VERSION ""

NS_ :

BS_:

BU_:

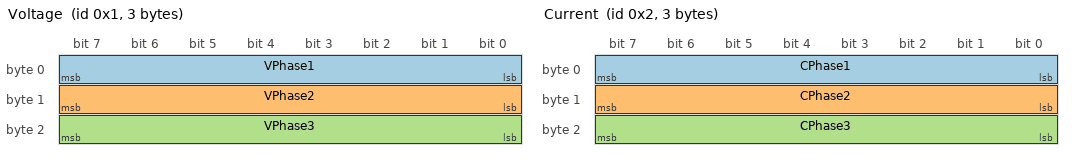
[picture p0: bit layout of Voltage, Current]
BO_ 1 Voltage: 3 ESP32
    SG_ VPhase1 : 0|8@1+ (1,0) [0|0] ""  VECTOR__INTEL
    SG_ VPhase2 : 8|8@1+ (1,0) [0|0] ""  VECTOR__INTEL
    SG_ VPhase3 : 16|8@1+ (1,0) [0|0] ""  VECTOR__INTEL

BO_ 2 Current: 3 ESP32
    SG_ CPhase1 : 0|8@1+ (1,0) [0|0] ""  VECTOR__INTEL
    SG_ CPhase2 : 8|8@1+ (1,0) [0|0] ""  VECTOR__INTEL
    SG_ CPhase3 : 16|8@1+ (1,0) [0|0] ""  VECTOR__INTEL
